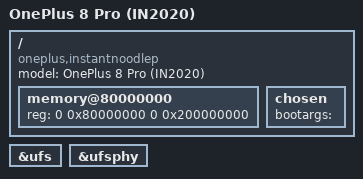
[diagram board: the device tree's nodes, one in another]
// SPDX-License-Identifier: BSD-3-Clause
// OnePlus 8 Pro (IN2020 / instantnoodlep), Qualcomm SM8250 (kona).
//
// Board description for the UniXNU ADT generator: memory, enabled CPUs and the
// peripherals a selected component consumes. Hardware facts come from the stock
// IN2020 boot_a/dtbo_a images and from the SoC repository's SM8250 register map.

/dts-v1/;
/include/ "sm8250.dtsi"

/ {
    model = "OnePlus 8 Pro (IN2020)";
    compatible = "oneplus,instantnoodlep", "qcom,sm8250";

    // DRAM: kona maps 8 GiB at 0x80000000 on this board (8 GiB SKU). The payload's
    // dram_size must agree with this node.
    memory@80000000 {
        device_type = "memory";
        reg = <0 0x80000000 0 0x200000000>;
    };

    // The bootloader leaves the display in its hand-off state; the panel is driven by
    // the firmware GOP until a display component with this panel's timing exists.
    chosen {
        bootargs = "";
    };
};

// Storage enabled 2026-11-20: the kona-adapted ShengUfs component (device-owned copy of
// official UniXNU/ShengUfs @f020bd6) is selected, so the ADT ufshc node now has a driver.
// Register/IRQ/clock facts: sm8250.dtsi + inputs/board/stock-base.dts; the stock node
// carries no dma-coherent property, so the driver's non-coherent cache maintenance path
// applies. PHY is the QMP v4 at 0x1d87000/0xe00 (stock), left in the firmware's state.
&ufs { status = "okay"; };
&ufsphy { status = "okay"; };
